# CY8C4245AXI_483 register map
File version: 0.1
PSoC 4200
Registers are 32-bit, read-write, no defined reset value unless marked. A register's access mark holds for its fields unless they carry their own. Offsets are from the block's base; lines under a group give offsets from that group; [hi:lo] are bit positions; {n}, {i} and the like mark numbered series; 'fields as' and 'values as' point back to an identical list; <NAME> marks a mode.

## Memory map
0x00000000 Opamp_1 — OpAmp
0x00000000 QuadDec_Front
0x00000000 UART — Serial Communication Block
0x00000000 QuadDec_Rear
0x00000000 PWM_Front
0x00000000 Motor_Current_ADC — Sequencing SAR ADC
0x00000000 PWM_Rear
0x400F0070 Front_Dir
0x400F0071 Rear_Dir

## Rear_Dir
Base 0x400F0071
0x00 Rear_Dir_CONTROL_REG 8-bit

## Front_Dir
Base 0x400F0070
Registers as Rear_Dir (with Rear_Dir read as Front_Dir).

## Opamp_1 — OpAmp
Base 0x00000000
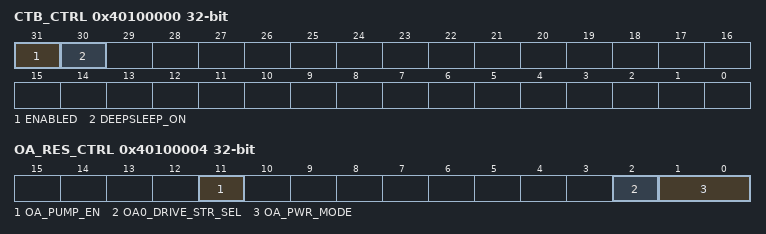
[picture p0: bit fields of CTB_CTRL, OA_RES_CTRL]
0x40100000 CTB_CTRL — Global CTB IP and power control
  [31] ENABLED — Selects component behavior in DeepSleep power mode
    0=DISABLE (CTB IP disabled (put analog in power down, open all switches)); 1=ENABLE (CTB IP enabledCTB IP enabled)
  [30] DEEPSLEEP_ON — Selects component behavior in DeepSleep power mode
    0=DISABLE (CTB IP disabled off during DeepSleep power mode); 1=ENABLE (CTB IP remains enabled during DeepSleep power mode (if ENABLED=1))
0x40100004 OA_RES_CTRL — Opamp and resistor control
  [11] OA_PUMP_EN — Selects pump
    0=DISABLE (Pump disabled); 1=ENABLE (Pump enabled)
  [2] OA0_DRIVE_STR_SEL — Opamp output strenght select
    0=Internal only; 1=Output to pin
  [1:0] OA_PWR_MODE — Selects power for opamp
    0=OFF; 1=LOW (Low power); 2=MED (Medium power); 3=HIGH (High power)
0x40100F08 OA_COMP_TRIM — Opamp Compenation Capacitor Trim
  [1:0] OA_COMP_TRIM
    1=HIGH_SPEED; 2=BALANCED; 3=HIGH_STABILITY

## QuadDec_Front
Base 0x00000000
0x40050148 COUNTER — Current counter value
0x4005014C CC — Compare / capture value
0x40050150 CC_BUF — Compare / capture buffer value
0x40050154 PERIOD — Period value
0x40050158 PERIOD_BUF — Period buffer value

## QuadDec_Rear
Base 0x00000000
0x40050188 COUNTER — Current counter value
0x4005018C CC — Compare / capture value
0x40050190 CC_BUF — Compare / capture buffer value
0x40050194 PERIOD — Period value
0x40050198 PERIOD_BUF — Period buffer value

## PWM_Front
Base 0x00000000
0x400501C8 COUNTER — Current counter value
0x400501CC CC — Compare / capture value
0x400501D0 CC_BUF — Compare / capture buffer value
0x400501D4 PERIOD — Period value
0x400501D8 PERIOD_BUF — Period buffer value

## PWM_Rear
Base 0x00000000
0x40050108 COUNTER — Current counter value
0x4005010C CC — Compare / capture value
0x40050110 CC_BUF — Compare / capture buffer value
0x40050114 PERIOD — Period value
0x40050118 PERIOD_BUF — Period buffer value
